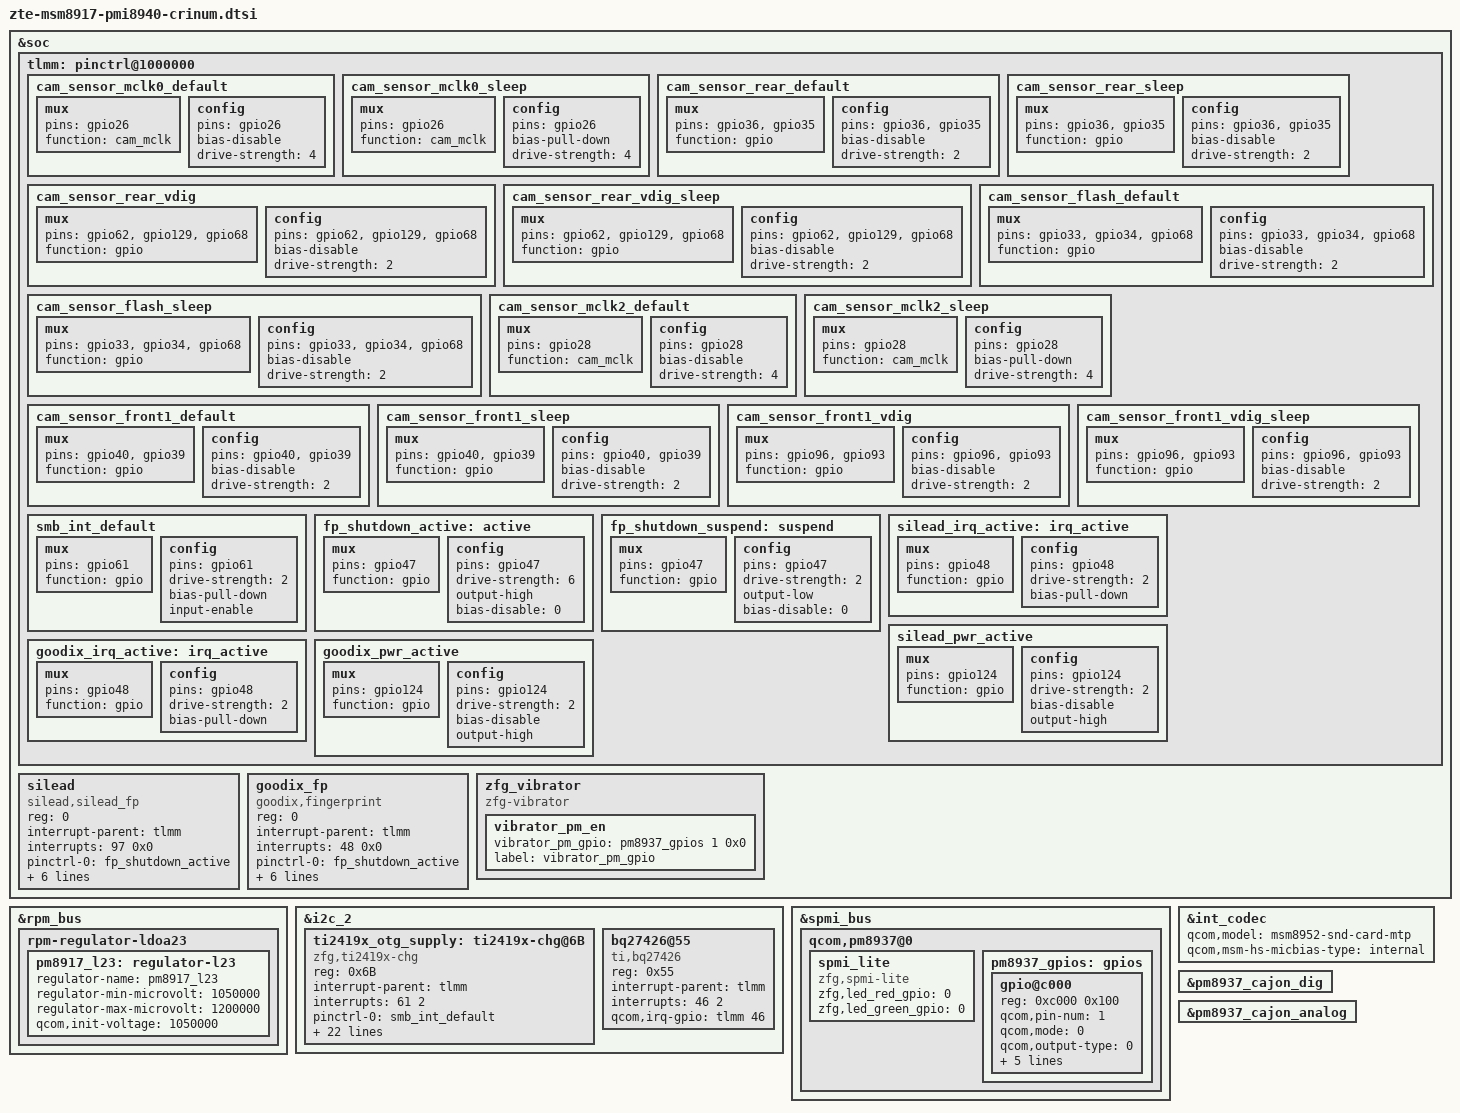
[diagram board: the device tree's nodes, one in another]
/*
 * Copyright (c) 2016, The Linux Foundation. All rights reserved.
 *
 * This program is free software; you can redistribute it and/or modify
 * it under the terms of the GNU General Public License version 2 and
 * only version 2 as published by the Free Software Foundation.
 *
 * This program is distributed in the hope that it will be useful,
 * but WITHOUT ANY WARRANTY; without even the implied warranty of
 * MERCHANTABILITY or FITNESS FOR A PARTICULAR PURPOSE.  See the
 * GNU General Public License for more details.
 */

/*
* device tree for zfg crinum board
*/


&soc {
	tlmm: pinctrl@1000000 {
	/*sensors */
		cam_sensor_mclk0_default: cam_sensor_mclk0_default {
			/* MCLK0 */
				mux {
				/* CLK, DATA */
				pins = "gpio26";
				function = "cam_mclk";
			};

			config {
				pins = "gpio26";
				bias-disable; /* No PULL */
				drive-strength = <4>; /* 2 MA */
			};
		};

		cam_sensor_mclk0_sleep: cam_sensor_mclk0_sleep {
			/* MCLK0 */
			mux {
				/* CLK, DATA */
				pins = "gpio26";
				function = "cam_mclk";
			};

			config {
				pins = "gpio26";
				bias-pull-down; /* PULL DOWN */
				drive-strength = <4>; /* 2 MA */
			};
		};

		cam_sensor_rear_default: cam_sensor_rear_default {
			/* RESET, STANDBY */
			mux {
				pins = "gpio36", "gpio35";
				function = "gpio";
			};

			config {
				pins = "gpio36","gpio35";
				bias-disable; /* No PULL */
				drive-strength = <2>; /* 2 MA */
			};
		};

		cam_sensor_rear_sleep: cam_sensor_rear_sleep {
			/* RESET, STANDBY */
			mux {
				pins = "gpio36","gpio35";
				function = "gpio";
			};

			config {
				pins = "gpio36","gpio35";
				bias-disable; /* No PULL */
				drive-strength = <2>; /* 2 MA */
			};
		};

		cam_sensor_rear_vdig: cam_sensor_rear_vdig {
			/* VDIG */
			mux {
				pins = "gpio62","gpio129","gpio68";
				function = "gpio";
			};

			config {
				pins = "gpio62","gpio129","gpio68";
				bias-disable; /* No PULL */
				drive-strength = <2>; /* 2 MA */
			};
		};

		cam_sensor_rear_vdig_sleep: cam_sensor_rear_vdig_sleep {
			/* VDIG */
			mux {
				pins = "gpio62","gpio129","gpio68";
				function = "gpio";
			};

			config {
				pins = "gpio62","gpio129","gpio68";
				bias-disable; /* No PULL */
				drive-strength = <2>; /* 2 MA */
			};
		};
		/*yuxin add for Z5151V flash 20180123 ++*/
		cam_sensor_flash_default: cam_sensor_flash_default {
			/* VDIG */
			mux {
				pins = "gpio33", "gpio34", "gpio68";
				function = "gpio";
			};

			config {
				pins = "gpio33", "gpio34", "gpio68";
				bias-disable; /* No PULL */
				drive-strength = <2>; /* 2 MA */
			};
		};

		cam_sensor_flash_sleep: cam_sensor_flash_sleep {
			/* VDIG */
			mux {
				pins = "gpio33", "gpio34", "gpio68";
				function = "gpio";
			};

			config {
				pins = "gpio33", "gpio34", "gpio68";
				bias-disable; /* No PULL */
				drive-strength = <2>; /* 2 MA */
			};
		};
	/*yuxin add for Z5151V flash 20180123 --*/
		cam_sensor_mclk2_default: cam_sensor_mclk2_default {
			/* MCLK2 */
			mux {
				/* CLK, DATA */
				pins = "gpio28";
				function = "cam_mclk";
			};

			config {
				pins = "gpio28";
				bias-disable; /* No PULL */
				drive-strength = <4>; /* 2 MA */
			};
		};

		cam_sensor_mclk2_sleep: cam_sensor_mclk2_sleep {
			/* MCLK2 */
			mux {
				/* CLK, DATA */
				pins = "gpio28";
				function = "cam_mclk";
			};

			config {
				pins = "gpio28";
				bias-pull-down; /* PULL DOWN */
				drive-strength = <4>; /* 2 MA */
			};
		};

		cam_sensor_front1_default: cam_sensor_front1_default {
			/* RESET, STANDBY */
			mux {
				pins = "gpio40", "gpio39";
				function = "gpio";
			};

			config {
				pins = "gpio40", "gpio39";
				bias-disable; /* No PULL */
				drive-strength = <2>; /* 2 MA */
			};
		};

		cam_sensor_front1_sleep: cam_sensor_front1_sleep {
			/* RESET, STANDBY */
			mux {
				pins = "gpio40", "gpio39";
				function = "gpio";
			};

			config {
				pins = "gpio40", "gpio39";
				bias-disable; /* No PULL */
				drive-strength = <2>; /* 2 MA */
			};
		};
		cam_sensor_front1_vdig: cam_sensor_front1_vdig {
			/* VDIG */
			mux {
				pins = "gpio96", "gpio93"; /*"gpio68" is used for rear cam too*/
				function = "gpio";
			};

			config {
				pins = "gpio96", "gpio93"; /*"gpio68" is used for rear cam too*/
				bias-disable; /* No PULL */
				drive-strength = <2>; /* 2 MA */
			};
		};

		cam_sensor_front1_vdig_sleep: cam_sensor_front1_vdig_sleep {
			/* VDIG */
			mux {
				pins = "gpio96", "gpio93"; /*"gpio68" is used for rear cam too*/
				function = "gpio";
			};

			config {
				pins = "gpio96", "gpio93"; /*"gpio68" is used for rear cam too*/
				bias-disable; /* No PULL */
				drive-strength = <2>; /* 2 MA */
			};
		};

		smb_int_default: smb_int_default {
			mux {
				pins = "gpio61";
				function = "gpio";
			};

			config {
				pins = "gpio61";
				drive-strength = <2>;
				bias-pull-down;
				input-enable;
			};
		};
	};
};
/*yuxin modify VREG_L23 voltage range for rear camera DVDD supply 20171222 begin*/
&rpm_bus {
	rpm-regulator-ldoa23 {
		status = "okay";
		pm8917_l23: regulator-l23 {
			regulator-name = "pm8917_l23";
			regulator-min-microvolt = <1050000>;
			regulator-max-microvolt = <1200000>;
			qcom,init-voltage = <1050000>;
			status = "okay";
		};
	};
};
/*yuxin modify VREG_L23 voltage range for rear camera DVDD supply 20171222 end*/



&tlmm {
	fp_shutdown_active:active{
		mux{
			pins = "gpio47";
			function = "gpio";
		};
		config{
			pins = "gpio47";
			drive-strength = <6>;
			output-high;
			bias-disable = <0>;
		};
	};

	fp_shutdown_suspend:suspend{
		mux{
			pins = "gpio47";
			function = "gpio";
		};
		config{
			pins = "gpio47";
			drive-strength = <2>;
			output-low;
			bias-disable = <0>;
		};
	};

	silead_irq_active:irq_active{
		mux{
			pins = "gpio48";
			function = "gpio";
		};
		config{
			pins = "gpio48";
			drive-strength = <2>;
			bias-pull-down;
		};
	};

	silead_pwr_active: silead_pwr_active {
		mux{
			pins = "gpio124";
			function = "gpio";
		};
		config {
			pins = "gpio124";
			drive-strength = <2>;
			bias-disable;
			output-high;
		};
	};

	goodix_irq_active: irq_active{
		mux{
			pins = "gpio48";
			function = "gpio";
		};
		config{
			pins = "gpio48";
			drive-strength = <2>;
			bias-pull-down;
		};
	};
	goodix_pwr_active: goodix_pwr_active {
		mux{
			pins = "gpio124";
			function = "gpio";
		};
		config {
			pins = "gpio124";
			drive-strength = <2>;
			bias-disable;
			output-high;
		};
	};
};
&soc {
	
	silead {
		status = "ok";
		reg = <0>;
		compatible = "silead,silead_fp";
		interrupt-parent = <&tlmm>;
		interrupts = <97 0x0>;

		pinctrl-names = "silead_active", "silead_suspend", "silead_irq", "pwr_active";
		pinctrl-0 = <&fp_shutdown_active>;
		pinctrl-1 = <&fp_shutdown_suspend>;
		pinctrl-2 = <&silead_irq_active>;
		pinctrl-3 = <&silead_pwr_active>;

		silead,gpio_reset = <&tlmm 47 0>;
		silead,gpio_irq = <&tlmm 48 0>;
		silead,gpio_pwr = <&tlmm 124 0>;
		interrupt-names = "sl_wake_up";
	};

	goodix_fp {
		status = "ok";
		reg = <0>;
		compatible = "goodix,fingerprint";
		interrupt-parent = <&tlmm>;
		interrupts = <48 0x0>;

		pinctrl-names = "goodix_active", "goodix_suspend", "goodix_irq", "pwr_active";
		pinctrl-0 = <&fp_shutdown_active>;
		pinctrl-1 = <&fp_shutdown_suspend>;
		pinctrl-2 = <&goodix_irq_active>;
		pinctrl-3 = <&goodix_pwr_active>;

		fp-gpio-reset = <&tlmm 47 0>;
		fp-gpio-irq = <&tlmm 48 0>;
		goodix,gpio_pwr = <&tlmm 124 0>;
		interrupt-names = "goodix_wake_up";
	};

	zfg_vibrator {
		compatible = "zfg-vibrator";
		vibrator_pm_en{
			vibrator_pm_gpio = <&pm8937_gpios 1 0x0>;
			label = "vibrator_pm_gpio";
		};
	};
};

&i2c_2 {
	ti2419x_otg_supply: ti2419x-chg@6B {
		compatible = "zfg,ti2419x-chg";
		reg = <0x6B>;
		interrupt-parent = <&tlmm>;
		interrupts = <61 2>;
		pinctrl-names = "default";
		pinctrl-0 = <&smb_int_default>;
		regulator-name = "ti2419x_otg_vreg";

		zfg,float-voltage-mv = <4350>;
		zfg,iterm-ma = <150>;
		
		
		zfg,recharge-thresh-mv = <100>;
		zfg,warm_recharge-thresh-mv = <50>;
		zfg,vbatdet-max-err-mv = <20>;
		zfg,charging-timeout = <10>;
		zfg,input_voltage_mv = <4520>;
		zfg,max_usb_current = <2100>;
		zfg,max_battery_current = <3000>;
		zfg,thermal-mitigation = <2100 1500 900 500 0>;
		zfg,warm_bat_mv = <4208>;
		zfg,cool_bat_mv = <4208>;
		zfg,warm-bat-decidegc = <440>;
		zfg,cool-bat-decidegc = <100>;
		zfg,hot-bat-decidegc = <500>;
		zfg,cold-bat-decidegc = <20>;
		zfg,warm_bat_chg_ma = <512>;
		zfg,cool_bat_chg_ma = <512>;
		qcom,tichg-vadc = <&pm8937_vadc>;
		zfg,batt-hot-percentage = <20>; /*Only for k81:-5~49*/
		zfg,batt-cold-percentage= <75>; /*Only for k81:-5~49*/
	};

	bq27426@55 {
		compatible = "ti,bq27426";
		reg = <0x55>;
		interrupt-parent = <&tlmm>;
		interrupts = <46 2>;
		qcom,irq-gpio = <&tlmm 46 0x0>;
	};
};

&spmi_bus {
	qcom,pm8937@0 {
		spmi_lite {
			compatible = "zfg,spmi-lite";
			zfg,led_red_gpio = <0>;
			zfg,led_green_gpio = <0>;
		};

		pm8937_gpios: gpios {
			gpio@c000 {
				reg = <0xc000 0x100>;
				qcom,pin-num = <1>;
				qcom,mode = <0>;
				qcom,output-type = <0>;
				qcom,pull = <0>;
				qcom,vin-sel = <3>;
				qcom,out-strength = <3>;
				qcom,src-sel = <0>;
				qcom,master-en = <0>;
				//qcom,dtest-sel = <1>;
				status = "okay";
			};
		};
	};
};

&int_codec {
	status = "okay";
	qcom,model = "msm8952-snd-card-mtp";
	qcom,msm-hs-micbias-type = "internal";
};

&pm8937_cajon_dig {
	status = "okay";
};

&pm8937_cajon_analog {
	status = "okay";
};
